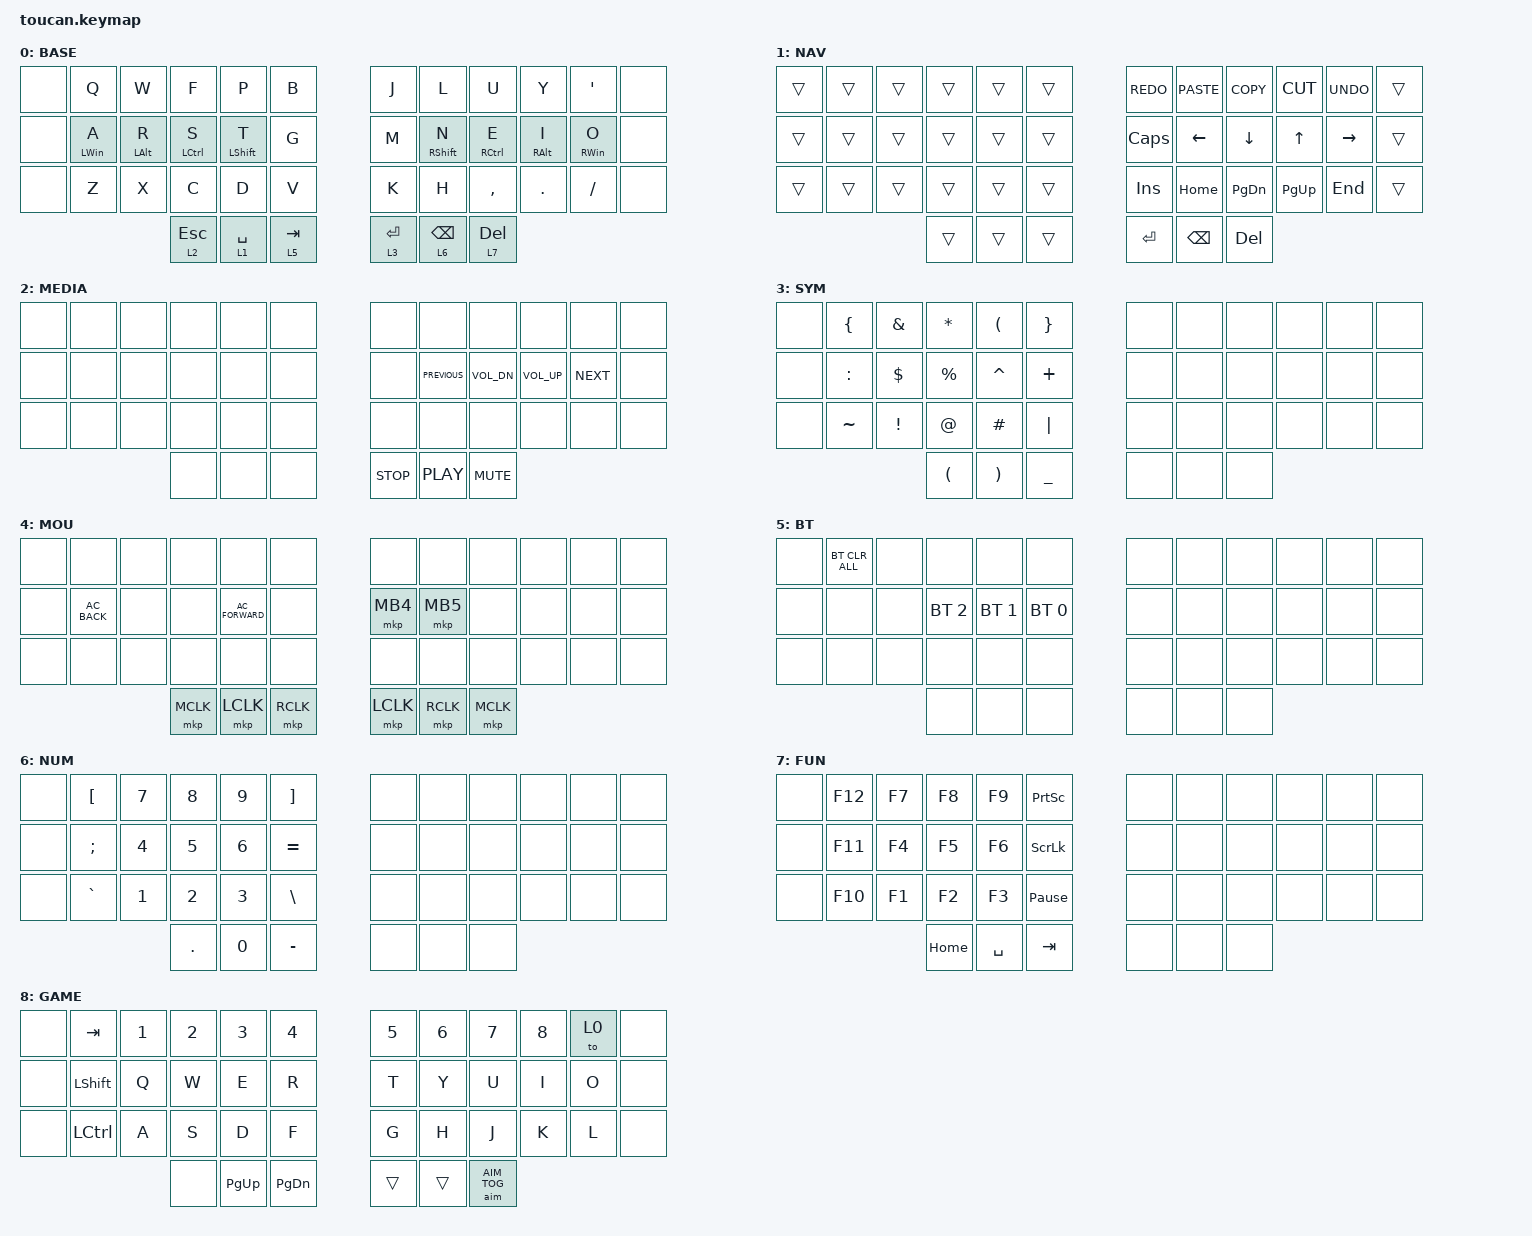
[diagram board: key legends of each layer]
#include <behaviors.dtsi>
#include <dt-bindings/zmk/bt.h>
#include <dt-bindings/zmk/keys.h>
#include <dt-bindings/zmk/pointing.h>
#include <behaviors/anti_idle_mode.dtsi>
#include <dt-bindings/anti_idle_mode.h>


/ {
    anti_idle {
        compatible = "zmk,anti-idle-generic";
        interval-ms = <60000>;
        bindings = <&mmv MOVE_DOWN &mmv MOVE_UP>;
        tap_ms = <40>;
        wait_ms = <200>;
    };

    combos {
        compatible = "zmk,combos";

        gaming {
            timeout-ms = <250>;
            key-positions = <36 41>;
            bindings = <&to 8>;
        };
    };

     behaviors {
        hm_mt: home_row_mod {
            compatible = "zmk,behavior-hold-tap";
            #binding-cells = <2>;
            flavor = "balanced";
            tapping-term-ms = <250>;
            quick-tap-ms = <175>;
            bindings = <&kp>, <&kp>;
        };
    };

    keymap {
        compatible = "zmk,keymap";

        base {
            display-name = "BASE";
            bindings = <
&none  &kp Q  &kp W  &kp F  &kp P  &kp B  &kp J  &kp L  &kp U  &kp Y  &kp SQT  &none  &none  &hm_mt LEFT_WIN A  &hm_mt LEFT_ALT R  &hm_mt LCTRL S  &hm_mt LEFT_SHIFT T  &kp G  &kp M  &hm_mt RSHFT N  &hm_mt RCTRL E  &hm_mt RIGHT_ALT I  &hm_mt RWIN O  &none  &none  &kp Z  &kp X  &kp C  &kp D  &kp V  &kp K  &kp H  &kp COMMA  &kp DOT  &kp FSLH  &none  &lt 2 ESC  &lt 1 SPACE  &lt 5 TAB  &lt 3 ENTER  &lt 6 BACKSPACE  &lt 7 DELETE
            >;
        };

        Nav {
            display-name = "NAV";
            bindings = <
&trans  &trans  &trans  &trans  &trans  &trans  &kp K_REDO  &kp K_PASTE  &kp K_COPY  &kp K_CUT  &kp K_UNDO  &trans  &trans  &trans  &trans  &trans  &trans  &trans  &kp CAPSLOCK  &kp LEFT_ARROW  &kp DOWN  &kp UP_ARROW  &kp RIGHT  &trans  &trans  &trans  &trans  &trans  &trans  &trans  &kp INS  &kp HOME  &kp PAGE_DOWN  &kp PG_UP  &kp END  &trans  &trans  &trans  &trans  &kp ENTER  &kp BACKSPACE  &kp DELETE
            >;
        };

        Media {
            display-name = "MEDIA";
            bindings = <
&none  &none  &none  &none  &none  &none  &none  &none  &none  &none  &none  &none  &none  &none  &none  &none  &none  &none  &none  &kp C_PREVIOUS  &kp C_VOL_DN  &kp C_VOLUME_UP  &kp C_NEXT  &none  &none  &none  &none  &none  &none  &none  &none  &none  &none  &none  &none  &none  &none  &none  &none  &kp C_STOP  &kp C_PLAY  &kp C_MUTE
            >;
        };

        Sym {
            display-name = "SYM";
            bindings = <
&none  &kp LEFT_BRACE  &kp AMPS  &kp ASTRK  &kp LEFT_PARENTHESIS  &kp RIGHT_BRACE  &none  &none  &none  &none  &none  &none  &none  &kp COLON  &kp DOLLAR  &kp PERCENT  &kp CARET  &kp PLUS  &none  &none  &none  &none  &none  &none  &none  &kp TILDE  &kp EXCLAMATION  &kp AT  &kp HASH  &kp PIPE  &none  &none  &none  &none  &none  &none  &kp LEFT_PARENTHESIS  &kp RIGHT_PARENTHESIS  &kp UNDERSCORE  &none  &none  &none
            >;
        };

        mouse {
            display-name = "MOU";
            bindings = <
&none  &none  &none  &none  &none  &none  &none  &none  &none  &none  &none  &none  &none  &kp C_AC_BACK  &none  &none  &kp C_AC_FORWARD  &none  &mkp MB4  &mkp MB5  &none  &none  &none  &none  &none  &none  &none  &none  &none  &none  &none  &none  &none  &none  &none  &none  &mkp MCLK  &mkp LCLK  &mkp RCLK  &mkp LCLK  &mkp RCLK  &mkp MCLK
            >;
        };

        BT {
            display-name = "BT";
            bindings = <
&none  &bt BT_CLR_ALL  &none  &none  &none  &none  &none  &none  &none  &none  &none  &none  &none  &none  &none  &bt BT_SEL 2  &bt BT_SEL 1  &bt BT_SEL 0  &none  &none  &none  &none  &none  &none  &none  &none  &none  &none  &none  &none  &none  &none  &none  &none  &none  &none  &none  &none  &none  &none  &none  &none
            >;
        };

        Num {
            display-name = "NUM";
            bindings = <
&none  &kp LBKT  &kp N7  &kp N8  &kp N9  &kp RBKT  &none  &none  &none  &none  &none  &none  &none  &kp SEMI  &kp N4  &kp N5  &kp N6  &kp EQUAL  &none  &none  &none  &none  &none  &none  &none  &kp GRAVE  &kp N1  &kp N2  &kp N3  &kp BSLH  &none  &none  &none  &none  &none  &none  &kp DOT  &kp N0  &kp MINUS  &none  &none  &none
            >;
        };

        Fun {
            display-name = "FUN";
            bindings = <
&none  &kp F12  &kp F7  &kp F8  &kp F9  &kp PRINTSCREEN  &none  &none  &none  &none  &none  &none  &none  &kp F11  &kp F4  &kp F5  &kp F6  &kp SCROLLLOCK  &none  &none  &none  &none  &none  &none  &none  &kp F10  &kp F1  &kp F2  &kp F3  &kp PAUSE_BREAK  &none  &none  &none  &none  &none  &none  &kp HOME  &kp SPACE  &kp TAB  &none  &none  &none
            >;
        };

        game {
            display-name = "GAME";
            bindings = <
&none     &kp TAB   &kp N1    &kp N2    &kp N3    &kp N4    &kp N5  &kp N6  &kp N7  &kp N8  &to 0  &none
&none     &kp LSHFT &kp Q     &kp W     &kp E     &kp R     &kp T   &kp Y   &kp U   &kp I   &kp O  &none
&none     &kp LCTRL &kp A     &kp S     &kp D     &kp F     &kp G   &kp H   &kp J   &kp K   &kp L  &none
&none     &kp PG_UP &kp PG_DN &trans    &trans    &aim AIM_TOG
            >;
        };
    };
};
